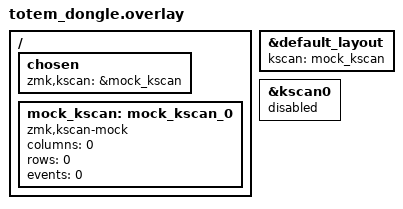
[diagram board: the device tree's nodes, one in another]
/*
 * Copyright (c) 2022 The ZMK Contributors
 *
 * SPDX-License-Identifier: MIT
 */

#include "totem.dtsi"

/ {
    chosen {
        zmk,kscan = &mock_kscan;
    };

    mock_kscan: mock_kscan_0 {
        compatible = "zmk,kscan-mock";
        columns = <0>;
        rows = <0>;
        events = <0>;
    };
};

&default_layout {
    kscan = <&mock_kscan>;
};

&kscan0 {
    status = "disabled";
};
